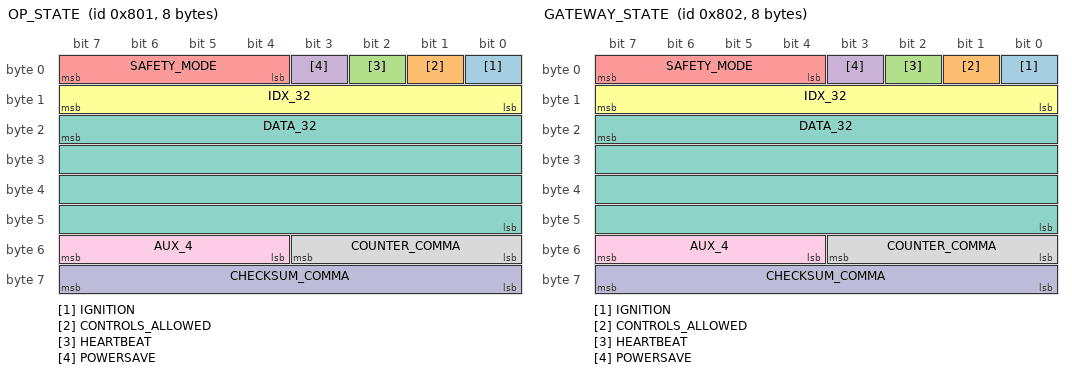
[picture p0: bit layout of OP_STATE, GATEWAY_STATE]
BO_ 2049 OP_STATE: 8 OP
 SG_ IGNITION : 0|1@0+ (1,0) [0|0] "" XXX
 SG_ CONTROLS_ALLOWED : 1|1@0+ (1,0) [0|0] "" XXX
 SG_ HEARTBEAT : 2|1@0+ (1,0) [0|0] "" XXX
 SG_ POWERSAVE : 3|1@0+ (1,0) [0|0] "" XXX
 SG_ SAFETY_MODE : 7|4@0+ (1,0) [0|0] "" XXX
 SG_ IDX_32 : 15|8@0+ (1,0) [0|0] "" XXX
 SG_ DATA_32 : 23|32@0+ (1,0) [0|0] "" XXX
 SG_ COUNTER_COMMA : 51|4@0+ (1,0) [0|0] "" XXX
 SG_ AUX_4 : 55|4@0+ (1,0) [0|0] "" XXX
 SG_ CHECKSUM_COMMA : 63|8@0+ (1,0) [0|0] "" XXX

BO_ 2050 GATEWAY_STATE: 8 GATEWAY
 SG_ IGNITION : 0|1@0+ (1,0) [0|0] "" XXX
 SG_ CONTROLS_ALLOWED : 1|1@0+ (1,0) [0|0] "" XXX
 SG_ HEARTBEAT : 2|1@0+ (1,0) [0|0] "" XXX
 SG_ POWERSAVE : 3|1@0+ (1,0) [0|0] "" XXX
 SG_ SAFETY_MODE : 7|4@0+ (1,0) [0|0] "" XXX
 SG_ IDX_32 : 15|8@0+ (1,0) [0|0] "" XXX
 SG_ DATA_32 : 23|32@0+ (1,0) [0|0] "" XXX
 SG_ COUNTER_COMMA : 51|4@0+ (1,0) [0|0] "" XXX
 SG_ AUX_4 : 55|4@0+ (1,0) [0|0] "" XXX
 SG_ CHECKSUM_COMMA : 63|8@0+ (1,0) [0|0] "" XXX

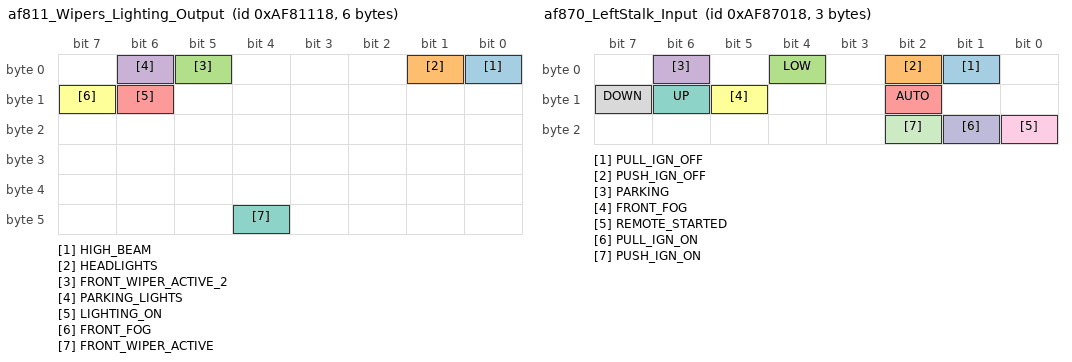
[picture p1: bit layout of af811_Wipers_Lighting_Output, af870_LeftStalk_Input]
BO_ 184029464 af811_Wipers_Lighting_Output: 6 BCM
 SG_ HIGH_BEAM : 0|1@0+ (1,0) [0|0] "" XXX
 SG_ HEADLIGHTS : 1|1@0+ (1,0) [0|0] "" XXX
 SG_ FRONT_WIPER_ACTIVE_2 : 5|1@0+ (1,0) [0|0] "" XXX
 SG_ PARKING_LIGHTS : 6|1@0+ (1,0) [0|0] "" XXX
 SG_ LIGHTING_ON : 14|1@0+ (1,0) [0|1] "" XXX
 SG_ FRONT_FOG : 15|1@0+ (1,0) [0|1] "" XXX
 SG_ FRONT_WIPER_ACTIVE : 44|1@0+ (1,0) [0|0] "" XXX

BO_ 184053784 af870_LeftStalk_Input: 3 BCM
 SG_ PULL_IGN_OFF : 1|1@0+ (1,0) [0|0] "" XXX
 SG_ PUSH_IGN_OFF : 2|1@0+ (1,0) [0|0] "" XXX
 SG_ LOW : 4|1@0+ (1,0) [0|0] "" XXX
 SG_ PARKING : 6|1@0+ (1,0) [0|0] "" XXX
 SG_ AUTO : 10|1@0+ (1,0) [0|0] "" XXX
 SG_ FRONT_FOG : 13|1@0+ (1,0) [0|0] "" XXX
 SG_ UP : 14|1@0+ (1,0) [0|0] "" XXX
 SG_ DOWN : 15|1@0+ (1,0) [0|0] "" XXX
 SG_ REMOTE_STARTED : 16|1@0+ (1,0) [0|0] "" XXX
 SG_ PULL_IGN_ON : 17|1@0+ (1,0) [0|0] "" XXX
 SG_ PUSH_IGN_ON : 18|1@0+ (1,0) [0|0] "" XXX

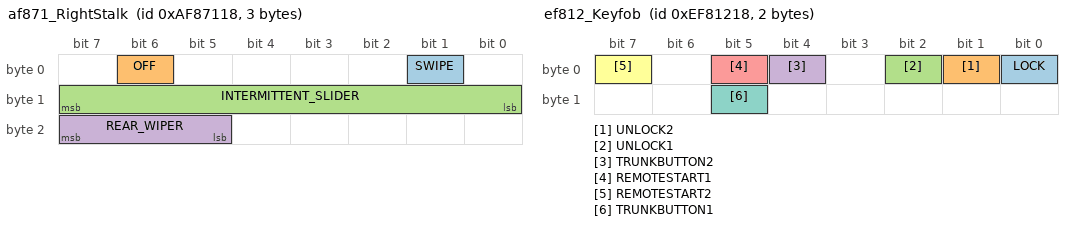
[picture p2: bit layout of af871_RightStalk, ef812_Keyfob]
BO_ 184054040 af871_RightStalk: 3 BCM
 SG_ SWIPE : 1|1@0+ (1,0) [0|0] "" XXX
 SG_ OFF : 6|1@0+ (1,0) [0|0] "" XXX
 SG_ INTERMITTENT_SLIDER : 15|8@0+ (1,0) [0|0] "" XXX
 SG_ REAR_WIPER : 23|3@0+ (1,0) [0|0] "" XXX

BO_ 184057168 af87d: 2 Meter

BO_ 184057368 af87e: 3 BCM

BO_ 184121680 af979: 1 Meter

BO_ 251138584 ef812_Keyfob: 2 BCM
 SG_ LOCK : 0|1@0+ (1,0) [0|0] "" XXX
 SG_ UNLOCK2 : 1|1@0+ (1,0) [0|0] "" XXX
 SG_ UNLOCK1 : 2|1@0+ (1,0) [0|0] "" XXX
 SG_ TRUNKBUTTON2 : 4|1@0+ (1,0) [0|0] "" XXX
 SG_ REMOTESTART1 : 5|1@0+ (1,0) [0|0] "" XXX
 SG_ REMOTESTART2 : 7|1@0+ (1,0) [0|0] "" XXX
 SG_ TRUNKBUTTON1 : 13|1@0+ (1,0) [0|0] "" XXX

BO_ 251138840 ef813: 6 RemoteSrtOrWakeup

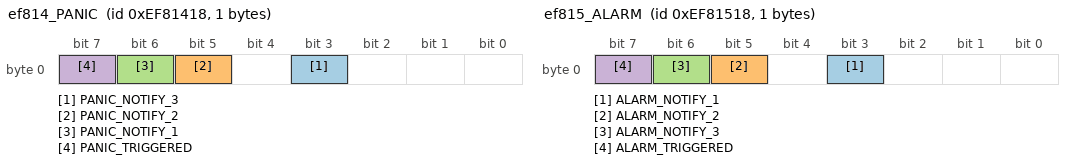
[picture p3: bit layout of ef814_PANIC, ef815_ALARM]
BO_ 251139096 ef814_PANIC: 1 BCM
 SG_ PANIC_NOTIFY_3 : 3|1@0+ (1,0) [0|0] "" XXX
 SG_ PANIC_NOTIFY_2 : 5|1@0+ (1,0) [0|0] "" XXX
 SG_ PANIC_NOTIFY_1 : 6|1@0+ (1,0) [0|0] "" XXX
 SG_ PANIC_TRIGGERED : 7|1@0+ (1,0) [0|0] "" XXX

BO_ 251139352 ef815_ALARM: 1 BCM
 SG_ ALARM_NOTIFY_1 : 3|1@0+ (1,0) [0|0] "" XXX
 SG_ ALARM_NOTIFY_2 : 5|1@0+ (1,0) [0|0] "" XXX
 SG_ ALARM_NOTIFY_3 : 6|1@0+ (1,0) [0|0] "" XXX
 SG_ ALARM_TRIGGERED : 7|1@0+ (1,0) [0|0] "" XXX

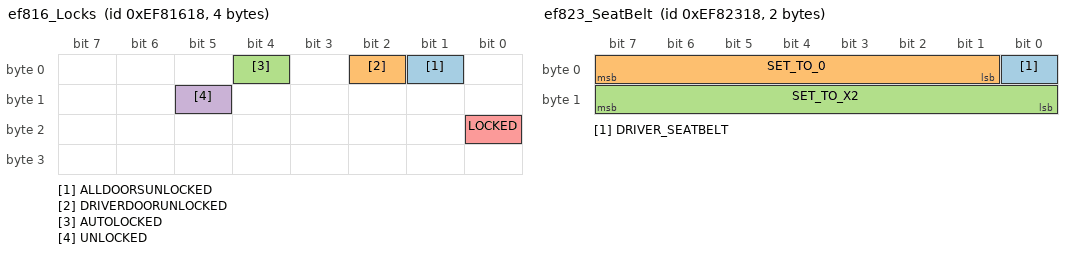
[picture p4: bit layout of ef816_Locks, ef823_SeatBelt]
BO_ 251139608 ef816_Locks: 4 BCM
 SG_ ALLDOORSUNLOCKED : 1|1@0+ (1,0) [0|0] "" XXX
 SG_ DRIVERDOORUNLOCKED : 2|1@0+ (1,0) [0|0] "" XXX
 SG_ AUTOLOCKED : 4|1@0+ (1,0) [0|0] "" XXX
 SG_ UNLOCKED : 13|1@0+ (1,0) [0|0] "" XXX
 SG_ LOCKED : 16|1@0+ (1,0) [0|0] "" XXX

BO_ 251139632 ef816: 8 RemoteSrtOrWakeup

BO_ 251142168 ef820_DoorLocks: 1 BCM
 SG_ SET_TO_0_ : 5|6@0+ (1,0) [0|0] "" XXX
 SG_ LOCKACTION_STATUS : 7|2@0+ (1,0) [0|0] "" XXX

BO_ 251142936 ef823_SeatBelt: 2 BCM
 SG_ DRIVER_SEATBELT : 0|1@0+ (1,0) [0|0] "" XXX
 SG_ SET_TO_0 : 7|7@0+ (1,0) [0|0] "" XXX
 SG_ SET_TO_X2 : 15|8@0+ (1,0) [0|0] "" XXX

BO_ 251143448 ef825: 1 RemoteSrtOrWakeup

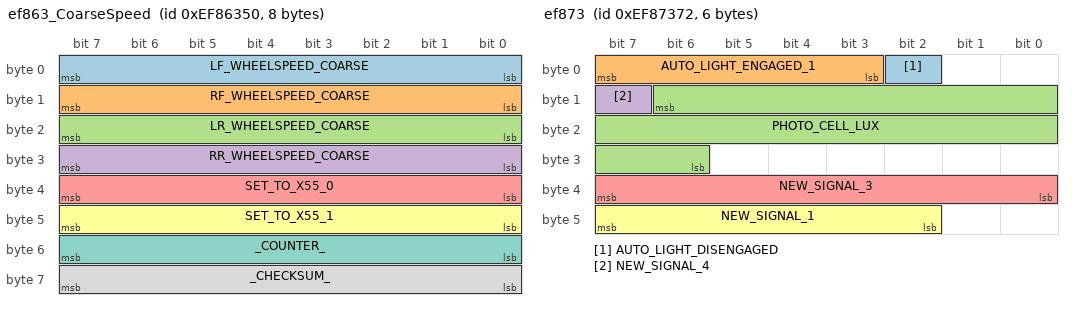
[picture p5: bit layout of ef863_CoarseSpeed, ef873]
BO_ 251159376 ef863_CoarseSpeed: 8 Meter
 SG_ LF_WHEELSPEED_COARSE : 0|8@1+ (1,0) [0|0] "" XXX
 SG_ RF_WHEELSPEED_COARSE : 8|8@1+ (1,0) [0|0] "" XXX
 SG_ LR_WHEELSPEED_COARSE : 16|8@1+ (1,0) [0|0] "" XXX
 SG_ RR_WHEELSPEED_COARSE : 24|8@1+ (1,0) [0|0] "" XXX
 SG_ SET_TO_X55_0 : 39|8@0+ (1,0) [0|0] "" XXX
 SG_ SET_TO_X55_1 : 47|8@0+ (1,0) [0|0] "" XXX
 SG_ _COUNTER_ : 55|8@0+ (1,0) [0|0] "" XXX
 SG_ _CHECKSUM_ : 63|8@0+ (1,0) [0|0] "" XXX

BO_ 251163506 ef873: 6 Solar
 SG_ AUTO_LIGHT_DISENGAGED : 2|1@0+ (1,0) [0|0] "" XXX
 SG_ AUTO_LIGHT_ENGAGED_1 : 7|5@0+ (1,0) [0|0] "" XXX
 SG_ PHOTO_CELL_LUX : 14|17@0+ (1,0) [0|0] "" XXX
 SG_ NEW_SIGNAL_4 : 15|1@0+ (1,0) [0|0] "" XXX
 SG_ NEW_SIGNAL_3 : 39|8@0+ (1,0) [0|0] "" XXX
 SG_ NEW_SIGNAL_1 : 47|6@0+ (1,0) [0|0] "" XXX

BO_ 251167000 ef881: 1 BCM

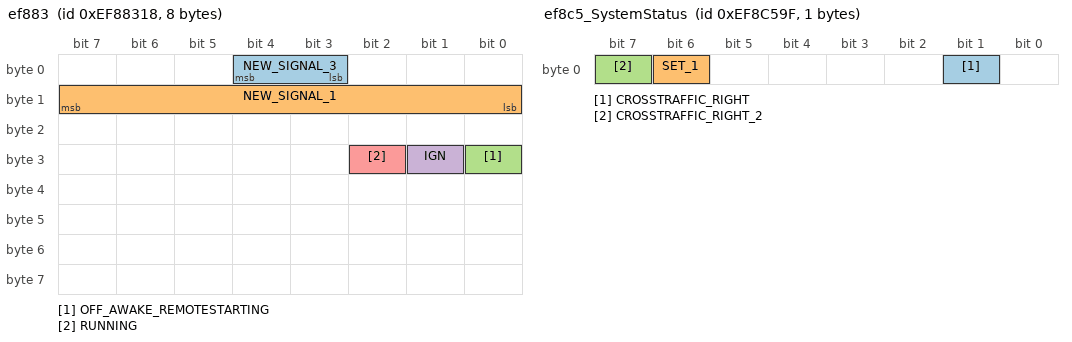
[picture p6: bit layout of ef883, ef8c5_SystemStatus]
BO_ 251167512 ef883: 8 BCM
 SG_ NEW_SIGNAL_3 : 4|2@0+ (1,0) [0|0] "" XXX
 SG_ NEW_SIGNAL_1 : 15|8@0+ (1,0) [0|0] "" XXX
 SG_ OFF_AWAKE_REMOTESTARTING : 24|1@0+ (1,0) [0|0] "" XXX
 SG_ IGN : 25|1@0+ (1,0) [0|0] "" XXX
 SG_ RUNNING : 26|1@0+ (1,0) [0|0] "" XXX

BO_ 251171864 ef894: 3 BCM

BO_ 251174936 ef8a0: 1 RemoteSrtOrWakeup

BO_ 251184543 ef8c5_SystemStatus: 1 BSI_L
 SG_ CROSSTRAFFIC_RIGHT : 1|1@0+ (1,0) [0|1] "" XXX
 SG_ SET_1 : 6|1@0+ (1,0) [0|1] "" XXX
 SG_ CROSSTRAFFIC_RIGHT_2 : 7|1@0+ (1,0) [0|1] "" XXX

BO_ 251203924 ef911: 3 Audio

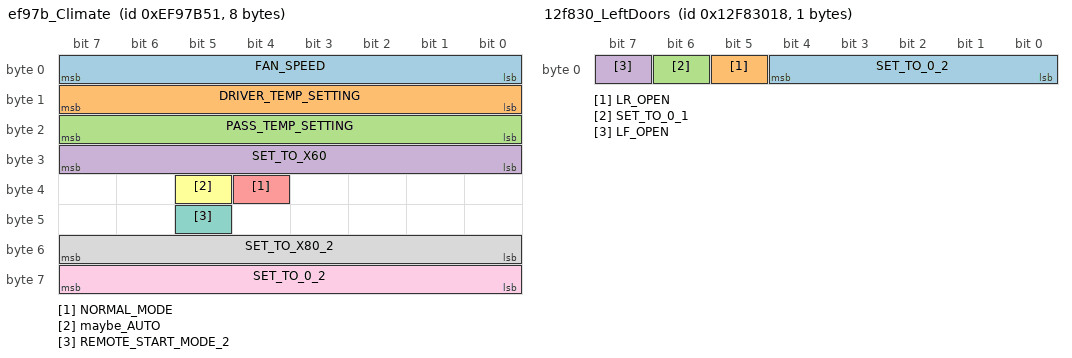
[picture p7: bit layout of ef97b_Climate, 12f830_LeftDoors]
BO_ 251231057 ef97b_Climate: 8 Climate
 SG_ FAN_SPEED : 0|8@1+ (1,0) [0|0] "" XXX
 SG_ DRIVER_TEMP_SETTING : 8|8@1+ (1,0) [0|0] "" XXX
 SG_ PASS_TEMP_SETTING : 16|8@1+ (1,0) [0|0] "" XXX
 SG_ SET_TO_X60 : 31|8@0+ (1,0) [0|0] "" XXX
 SG_ NORMAL_MODE : 36|1@0+ (1,0) [0|0] "" XXX
 SG_ maybe_AUTO : 37|1@0+ (1,0) [0|0] "" XXX
 SG_ REMOTE_START_MODE_2 : 45|1@0+ (1,0) [0|0] "" XXX
 SG_ SET_TO_X80_2 : 55|8@0+ (1,0) [0|0] "" XXX
 SG_ SET_TO_0_2 : 63|8@0+ (1,0) [0|0] "" XXX

BO_ 251234129 ef987: 3 Climate

BO_ 251234897 ef98a: 2 Climate
 SG_ TempRelated : 7|8@0+ (1,0) [0|0] "" XXX
 SG_ NEW_SIGNAL_1 : 13|6@0+ (1,0) [0|0] "" XXX
 SG_ SomeState : 15|2@0+ (1,0) [0|0] "" XXX

BO_ 251235152 ef98b_Fuel: 7 Meter
 SG_ NEW_SIGNAL_1 : 7|8@0+ (1,0) [0|0] "" XXX
 SG_ Fuel_idk : 15|8@0+ (1,0) [0|0] "" XXX
 SG_ NEW_SIGNAL_3 : 23|8@0+ (1,0) [0|0] "" XXX
 SG_ 0s : 31|32@0+ (1,0) [0|0] "" XXX

BO_ 303169360 1211ff: 0 RemoteSrtOrWakeup

BO_ 317390672 12eaff_50: 2 RemoteSrtOrWakeup

BO_ 317390673 12eaff_51: 2 RemoteSrtOrWakeup

BO_ 317390676 12eaff_QueryAllModules: 2 Audio
 SG_ NEW_SIGNAL_1 : 7|8@0+ (1,0) [0|255] "" XXX
 SG_ ReturnID : 15|8@0+ (1,0) [0|0] "" XXX

BO_ 318246936 12f810_Lighting: 6 BCM
 SG_ NEW_SIGNAL_6 : 0|3@1+ (1,0) [0|0] "" XXX
 SG_ SET_TO_1_1 : 3|1@0+ (1,0) [0|0] "" XXX
 SG_ PEDAL_BRAKE_OUTPUT : 4|1@0+ (1,0) [0|0] "" XXX
 SG_ SET_TO_1_2 : 5|1@0+ (1,0) [0|0] "" XXX
 SG_ NEW_SIGNAL_7 : 7|2@0+ (1,0) [0|0] "" XXX
 SG_ NEW_SIGNAL_5 : 15|8@0+ (1,0) [0|0] "" XXX
 SG_ NEW_SIGNAL_3 : 18|3@0+ (1,0) [0|0] "" XXX
 SG_ RIGHTSIGNAL : 19|1@0+ (1,0) [0|0] "" XXX
 SG_ LEFTSIGNAL : 20|1@0+ (1,0) [0|0] "" XXX
 SG_ HAZARDS_ENABLE : 21|1@0+ (1,0) [0|0] "" XXX
 SG_ NEW_SIGNAL_4 : 22|1@0+ (1,0) [0|0] "" XXX
 SG_ SET_TO_1_3 : 23|1@0+ (1,0) [0|0] "" XXX
 SG_ NEW_SIGNAL_2 : 30|7@0+ (1,0) [0|0] "" XXX
 SG_ REVERSE : 31|1@0+ (1,0) [0|0] "" XXX
 SG_ NEW_SIGNAL_1 : 37|6@0+ (1,0) [0|0] "" XXX
 SG_ AUTORIGHT : 38|1@0+ (1,0) [0|0] "" XXX
 SG_ AUTOLEFT : 39|1@0+ (1,0) [0|0] "" XXX
 SG_ SET_TO_C0 : 47|8@0+ (1,0) [0|0] "" XXX

BO_ 318251544 12f822: 1 BCM

BO_ 318254104 12f82c: 1 BCM

BO_ 318255128 12f830_LeftDoors: 1 BCM
 SG_ SET_TO_0_2 : 4|5@0+ (1,0) [0|0] "" XXX
 SG_ LR_OPEN : 5|1@0+ (1,0) [0|0] "" XXX
 SG_ SET_TO_0_1 : 6|1@0+ (1,0) [0|0] "" XXX
 SG_ LF_OPEN : 7|1@0+ (1,0) [0|0] "" XXX

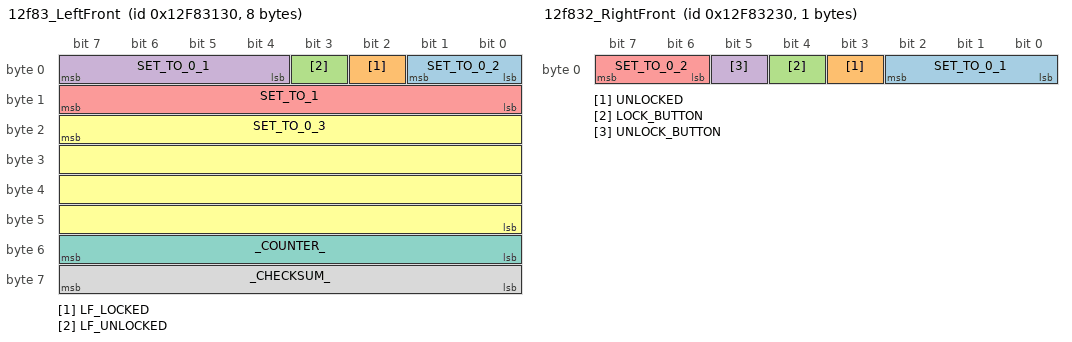
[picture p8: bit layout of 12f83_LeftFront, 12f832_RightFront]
BO_ 318255408 12f83_LeftFront: 8 WindowMain
 SG_ SET_TO_0_2 : 0|2@1+ (1,0) [0|0] "" XXX
 SG_ LF_LOCKED : 2|1@0+ (1,0) [0|0] "" XXX
 SG_ LF_UNLOCKED : 3|1@0+ (1,0) [0|0] "" XXX
 SG_ SET_TO_0_1 : 7|4@0+ (1,0) [0|0] "" XXX
 SG_ SET_TO_1 : 15|8@0+ (1,0) [0|0] "" XXX
 SG_ SET_TO_0_3 : 23|32@0+ (1,0) [0|0] "" XXX
 SG_ _COUNTER_ : 48|8@1+ (1,0) [0|0] "" XXX
 SG_ _CHECKSUM_ : 56|8@1+ (1,0) [0|0] "" XXX

BO_ 318255664 12f832_RightFront: 1 WindowMain
 SG_ SET_TO_0_1 : 0|3@1+ (1,0) [0|0] "" XXX
 SG_ UNLOCKED : 3|1@0+ (1,0) [0|0] "" XXX
 SG_ LOCK_BUTTON : 4|1@0+ (1,0) [0|0] "" XXX
 SG_ UNLOCK_BUTTON : 5|1@0+ (1,0) [0|0] "" XXX
 SG_ SET_TO_0_2 : 7|2@0+ (1,0) [0|0] "" XXX

BO_ 318256152 12f834: 1 BCM

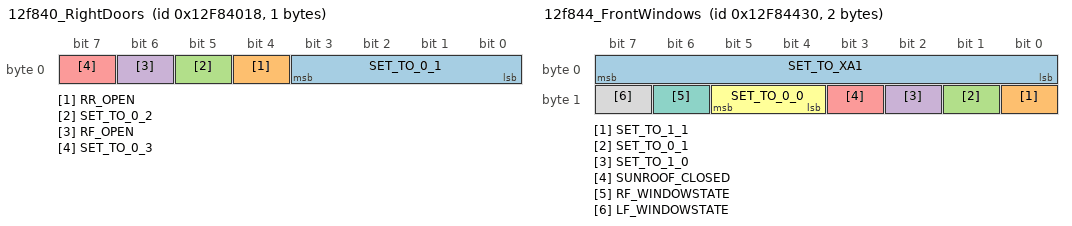
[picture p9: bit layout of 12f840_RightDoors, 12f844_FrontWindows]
BO_ 318259224 12f840_RightDoors: 1 BCM
 SG_ SET_TO_0_1 : 3|4@0+ (1,0) [0|0] "" XXX
 SG_ RR_OPEN : 4|1@0+ (1,0) [0|0] "" XXX
 SG_ SET_TO_0_2 : 5|1@0+ (1,0) [0|0] "" XXX
 SG_ RF_OPEN : 6|1@0+ (1,0) [0|0] "" XXX
 SG_ SET_TO_0_3 : 7|1@0+ (1,0) [0|0] "" XXX

BO_ 318259480 12f841_LeftRear: 1 BCM
 SG_ SET_TO_0_1 : 6|7@0+ (1,0) [0|0] "" XXX
 SG_ UNLOCKED : 7|1@0+ (1,0) [0|0] "" XXX

BO_ 318259736 12f842_RightRear: 1 BCM
 SG_ SET_TO_0_1 : 6|7@0+ (1,0) [0|0] "" XXX
 SG_ UNLOCKED : 7|1@0+ (1,0) [0|0] "" XXX

BO_ 318259992 12f843_Trunk: 1 BCM
 SG_ SET_TO_0_1 : 6|7@0+ (1,0) [0|0] "" XXX
 SG_ TRUNK_OPEN : 7|1@0+ (1,0) [0|0] "" XXX

BO_ 318260272 12f844_FrontWindows: 2 WindowMain
 SG_ SET_TO_XA1 : 7|8@0+ (1,0) [0|0] "" XXX
 SG_ SET_TO_1_1 : 8|1@0+ (1,0) [0|0] "" XXX
 SG_ SET_TO_0_1 : 9|1@0+ (1,0) [0|0] "" XXX
 SG_ SET_TO_1_0 : 10|1@0+ (1,0) [0|0] "" XXX
 SG_ SUNROOF_CLOSED : 11|1@0+ (1,0) [0|0] "" XXX
 SG_ SET_TO_0_0 : 13|2@0+ (1,0) [0|0] "" XXX
 SG_ RF_WINDOWSTATE : 14|1@0+ (1,0) [0|0] "" XXX
 SG_ LF_WINDOWSTATE : 15|1@0+ (1,0) [0|0] "" XXX

BO_ 318261784 12f84a: 1 BCM

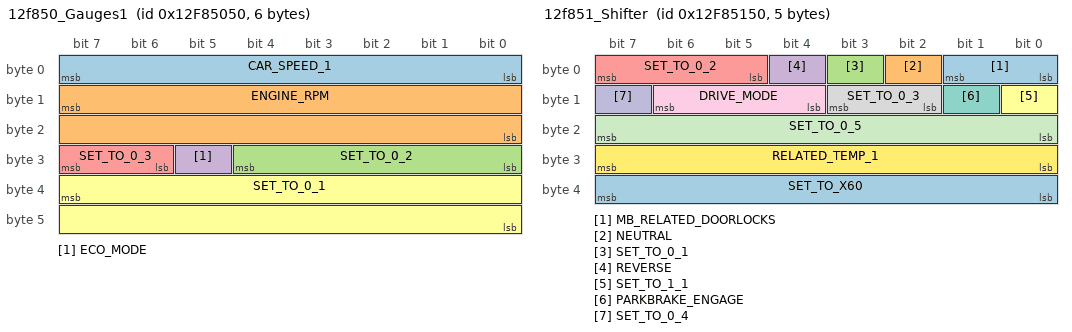
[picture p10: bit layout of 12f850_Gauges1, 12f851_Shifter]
BO_ 318263376 12f850_Gauges1: 6 Meter
 SG_ CAR_SPEED_1 : 7|8@0+ (1,0) [0|0] "" XXX
 SG_ ENGINE_RPM : 15|16@0+ (1,0) [0|0] "" XXX
 SG_ SET_TO_0_2 : 28|5@0+ (1,0) [0|0] "" XXX
 SG_ ECO_MODE : 29|1@0+ (1,0) [0|0] "" XXX
 SG_ SET_TO_0_3 : 31|2@0+ (1,0) [0|0] "" XXX
 SG_ SET_TO_0_1 : 39|16@0+ (1,0) [0|0] "" XXX

BO_ 318263632 12f851_Shifter: 5 Meter
 SG_ MB_RELATED_DOORLOCKS : 1|2@0+ (1,0) [0|0] "" XXX
 SG_ NEUTRAL : 2|1@0+ (1,0) [0|0] "" XXX
 SG_ SET_TO_0_1 : 3|1@0+ (1,0) [0|0] "" XXX
 SG_ REVERSE : 4|1@0+ (1,0) [0|0] "" XXX
 SG_ SET_TO_0_2 : 7|3@0+ (1,0) [0|0] "" XXX
 SG_ SET_TO_1_1 : 8|1@0+ (1,0) [0|0] "" XXX
 SG_ PARKBRAKE_ENGAGE : 9|1@0+ (1,0) [0|0] "" XXX
 SG_ SET_TO_0_3 : 10|2@1+ (1,0) [0|0] "" XXX
 SG_ DRIVE_MODE : 14|3@0+ (1,0) [0|0] "" XXX
 SG_ SET_TO_0_4 : 15|1@0+ (1,0) [0|0] "" XXX
 SG_ SET_TO_0_5 : 23|8@0+ (1,0) [0|0] "" XXX
 SG_ RELATED_TEMP_1 : 31|8@0+ (1,0) [0|0] "" XXX
 SG_ SET_TO_X60 : 39|8@0+ (1,0) [0|0] "" XXX

BO_ 318263888 12f852: 4 Meter

BO_ 318264145 12f853: 8 Climate
 SG_ INTERIOR_TEMP : 7|8@0+ (1,0) [0|0] "" XXX
 SG_ NEW_SIGNAL_1 : 55|16@0+ (1,0) [0|0] "" XXX

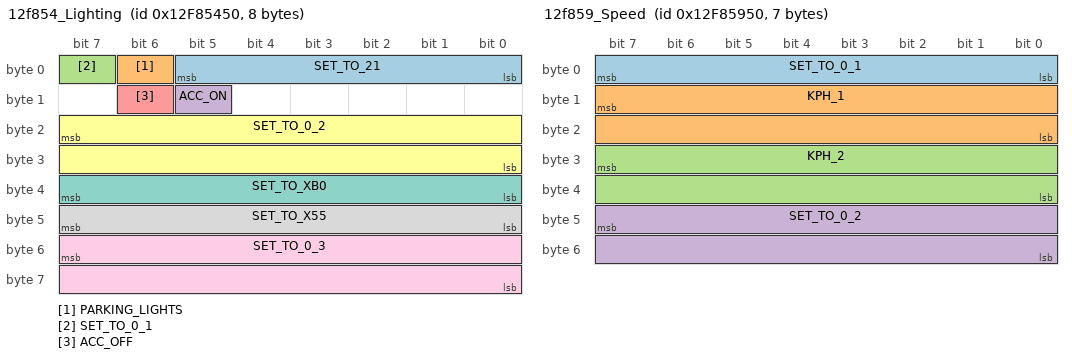
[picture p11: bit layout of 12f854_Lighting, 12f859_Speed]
BO_ 318264400 12f854_Lighting: 8 Meter
 SG_ SET_TO_21 : 5|6@0+ (1,0) [0|0] "" XXX
 SG_ PARKING_LIGHTS : 6|1@0+ (1,0) [0|0] "" XXX
 SG_ SET_TO_0_1 : 7|1@0+ (1,0) [0|0] "" XXX
 SG_ ACC_ON : 13|1@0+ (1,0) [0|0] "" XXX
 SG_ ACC_OFF : 14|1@0+ (1,0) [0|0] "" XXX
 SG_ SET_TO_0_2 : 23|16@0+ (1,0) [0|0] "" XXX
 SG_ SET_TO_XB0 : 39|8@0+ (1,0) [0|0] "" XXX
 SG_ SET_TO_X55 : 47|8@0+ (1,0) [0|0] "" XXX
 SG_ SET_TO_0_3 : 55|16@0+ (1,0) [0|0] "" XXX

BO_ 318265425 12f858: 6 Climate
 SG_ INTERIOR_TEMP : 7|8@0+ (1,0) [0|0] "" XXX
 SG_ EXTERIOR_TEMP : 31|8@0+ (1,0) [0|0] "" XXX

BO_ 318265680 12f859_Speed: 7 Meter
 SG_ SET_TO_0_1 : 7|8@0+ (1,0) [0|0] "" XXX
 SG_ KPH_1 : 15|16@0+ (0.01,0) [0|0] "" XXX
 SG_ KPH_2 : 31|16@0+ (0.01,0) [0|0] "" XXX
 SG_ SET_TO_0_2 : 47|16@0+ (1,0) [0|0] "" XXX

BO_ 318266448 12f85c: 6 Meter

BO_ 318267728 12f861: 8 Meter

BO_ 318273560 12f878: 1 BCM

BO_ 318275608 12f880_TrunkButton: 1 BCM
 SG_ SET_TO_0_1 : 6|7@0+ (1,0) [0|0] "" XXX
 SG_ RELEASE_BUTTON : 7|1@0+ (1,0) [0|0] "" XXX

BO_ 318279704 12f890: 4 BCM
 SG_ State_idk : 8|2@1+ (1,0) [0|0] "" XXX
 SG_ Starter_idk : 26|1@0+ (1,0) [0|0] "" XXX

BO_ 318284336 12f8a2: 8 WindowMain

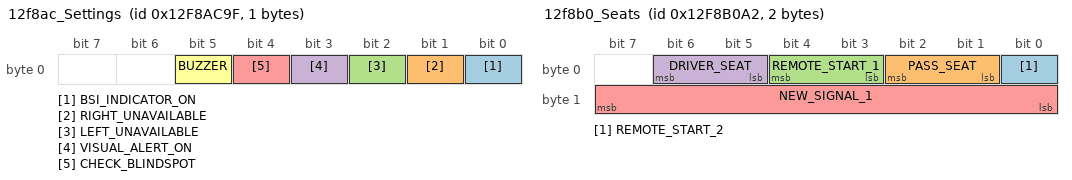
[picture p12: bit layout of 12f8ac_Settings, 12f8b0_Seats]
BO_ 318287007 12f8ac_Settings: 1 BSI_L
 SG_ BSI_INDICATOR_ON : 0|1@0+ (1,0) [0|1] "" XXX
 SG_ RIGHT_UNAVAILABLE : 1|1@0+ (1,0) [0|1] "" XXX
 SG_ LEFT_UNAVAILABLE : 2|1@0+ (1,0) [0|1] "" XXX
 SG_ VISUAL_ALERT_ON : 3|1@0+ (1,0) [0|1] "" XXX
 SG_ CHECK_BLINDSPOT : 4|1@0+ (1,0) [0|3] "" XXX
 SG_ BUZZER : 5|1@0+ (1,0) [0|1] "" XXX

BO_ 318288034 12f8b0_Seats: 2 HeatedSeats
 SG_ REMOTE_START_2 : 0|1@0+ (1,0) [0|0] "" XXX
 SG_ PASS_SEAT : 2|2@0+ (1,0) [0|0] "" XXX
 SG_ REMOTE_START_1 : 4|2@0+ (1,0) [0|0] "" XXX
 SG_ DRIVER_SEAT : 6|2@0+ (1,0) [0|0] "" XXX
 SG_ NEW_SIGNAL_1 : 15|8@0+ (1,0) [0|0] "" XXX

BO_ 318288209 12f8b1: 4 Climate

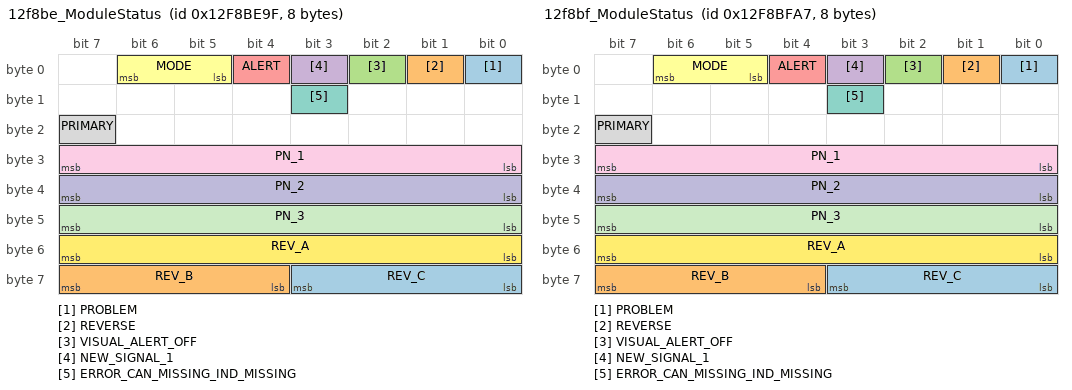
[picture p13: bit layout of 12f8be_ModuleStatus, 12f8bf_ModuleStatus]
BO_ 318291615 12f8be_ModuleStatus: 8 BSI_L
 SG_ PROBLEM : 0|1@0+ (1,0) [0|1] "" XXX
 SG_ REVERSE : 1|1@0+ (1,0) [0|1] "" XXX
 SG_ VISUAL_ALERT_OFF : 2|1@0+ (1,0) [0|1] "" XXX
 SG_ NEW_SIGNAL_1 : 3|1@0+ (1,0) [0|1] "" XXX
 SG_ ALERT : 4|1@0+ (1,0) [0|0] "" XXX
 SG_ MODE : 6|2@0+ (1,0) [0|0] "" XXX
 SG_ ERROR_CAN_MISSING_IND_MISSING : 11|1@0+ (1,0) [0|1] "" XXX
 SG_ PRIMARY : 23|1@0+ (1,0) [0|0] "" XXX
 SG_ PN_1 : 31|8@0+ (1,0) [0|0] "" XXX
 SG_ PN_2 : 39|8@0+ (1,0) [0|0] "" XXX
 SG_ PN_3 : 47|8@0+ (1,0) [0|0] "" XXX
 SG_ REV_A : 55|8@0+ (1,0) [0|0] "" XXX
 SG_ REV_C : 59|4@0+ (1,0) [0|0] "" XXX
 SG_ REV_B : 63|4@0+ (1,0) [0|0] "" XXX

BO_ 318291879 12f8bf_ModuleStatus: 8 BSI_R
 SG_ PROBLEM : 0|1@0+ (1,0) [0|1] "" XXX
 SG_ REVERSE : 1|1@0+ (1,0) [0|1] "" XXX
 SG_ VISUAL_ALERT_OFF : 2|1@0+ (1,0) [0|1] "" XXX
 SG_ NEW_SIGNAL_1 : 3|1@0+ (1,0) [0|1] "" XXX
 SG_ ALERT : 4|1@0+ (1,0) [0|0] "" XXX
 SG_ MODE : 6|2@0+ (1,0) [0|0] "" XXX
 SG_ ERROR_CAN_MISSING_IND_MISSING : 11|1@0+ (1,0) [0|1] "" XXX
 SG_ PRIMARY : 23|1@0+ (1,0) [0|0] "" XXX
 SG_ PN_1 : 31|8@0+ (1,0) [0|0] "" XXX
 SG_ PN_2 : 39|8@0+ (1,0) [0|0] "" XXX
 SG_ PN_3 : 47|8@0+ (1,0) [0|0] "" XXX
 SG_ REV_A : 55|8@0+ (1,0) [0|0] "" XXX
 SG_ REV_C : 59|4@0+ (1,0) [0|0] "" XXX
 SG_ REV_B : 63|4@0+ (1,0) [0|0] "" XXX

BO_ 318292308 12f8c1_Location: 8 Audio
 SG_ NEW_SIGNAL_1 : 9|16@0+ (1,0) [0|16383] "" XXX
 SG_ NEW_SIGNAL_2 : 40|15@0+ (1,0) [0|16383] "" XXX

BO_ 318300244 12f8e0: 8 Audio
 SG_ NEW_SIGNAL_1 : 7|8@0+ (1,0) [0|255] "" XXX
 SG_ NEW_SIGNAL_2 : 15|8@0+ (1,0) [0|255] "" XXX
 SG_ NEW_SIGNAL_3 : 59|1@0+ (1,0) [0|1] "" XXX

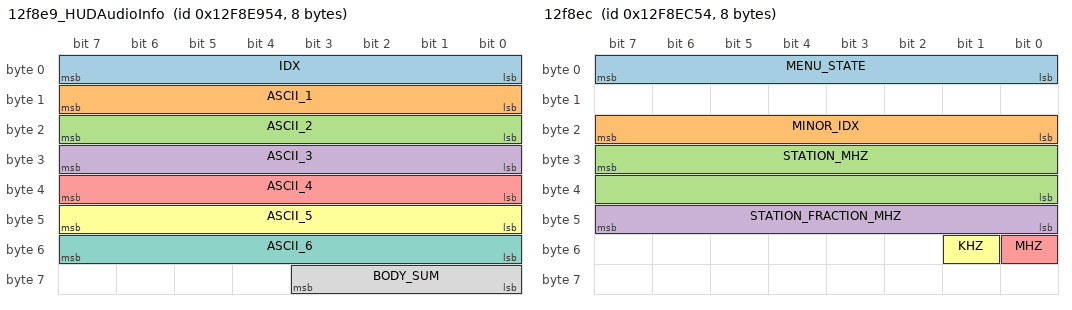
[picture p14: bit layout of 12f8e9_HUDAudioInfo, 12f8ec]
BO_ 318302548 12f8e9_HUDAudioInfo: 8 Audio
 SG_ IDX : 7|8@0+ (1,0) [0|0] "" XXX
 SG_ ASCII_1 : 15|8@0+ (1,0) [0|0] "" XXX
 SG_ ASCII_2 : 23|8@0+ (1,0) [0|0] "" XXX
 SG_ ASCII_3 : 31|8@0+ (1,0) [0|0] "" XXX
 SG_ ASCII_4 : 39|8@0+ (1,0) [0|0] "" XXX
 SG_ ASCII_5 : 47|8@0+ (1,0) [0|0] "" XXX
 SG_ ASCII_6 : 55|8@0+ (1,0) [0|0] "" XXX
 SG_ BODY_SUM : 59|4@0+ (1,0) [0|0] "" XXX

BO_ 318302800 12f8ea: 8 Meter
 SG_ CHANGES_WITH_TRACK_CHANGE : 39|8@0+ (1,0) [0|0] "" XXX

BO_ 318303316 12f8ec: 8 Audio
 SG_ MENU_STATE : 7|8@0+ (1,0) [0|0] "" XXX
 SG_ MINOR_IDX : 23|8@0+ (1,0) [0|0] "" XXX
 SG_ STATION_MHZ : 31|16@0+ (1,0) [0|0] "" XXX
 SG_ STATION_FRACTION_MHZ : 47|8@0+ (1,0) [0|0] "" XXX
 SG_ MHZ : 48|1@0+ (1,0) [0|0] "" XXX
 SG_ KHZ : 49|1@0+ (1,0) [0|0] "" XXX

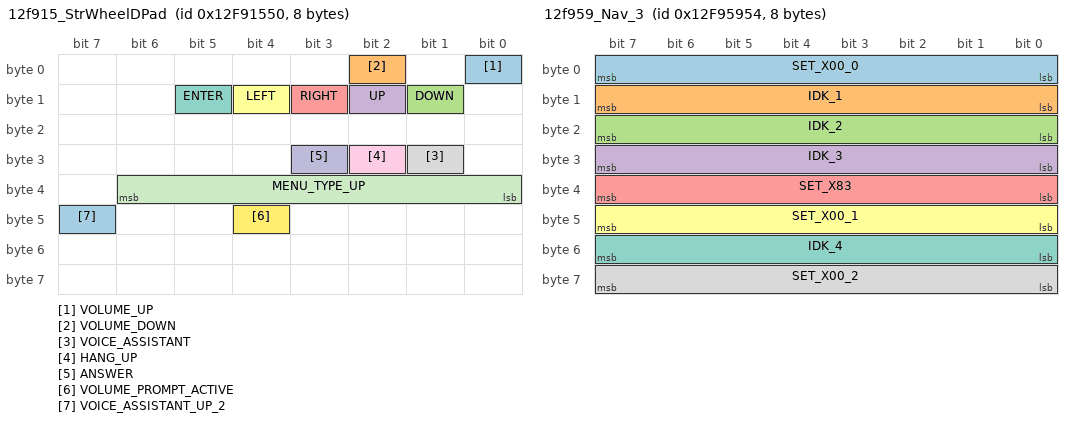
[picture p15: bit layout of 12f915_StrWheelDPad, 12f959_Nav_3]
BO_ 318313808 12f915_StrWheelDPad: 8 Meter
 SG_ VOLUME_UP : 0|1@0+ (1,0) [0|0] "" XXX
 SG_ VOLUME_DOWN : 2|1@0+ (1,0) [0|0] "" XXX
 SG_ DOWN : 9|1@0+ (1,0) [0|0] "" XXX
 SG_ UP : 10|1@0+ (1,0) [0|0] "" XXX
 SG_ RIGHT : 11|1@0+ (1,0) [0|0] "" XXX
 SG_ LEFT : 12|1@0+ (1,0) [0|0] "" XXX
 SG_ ENTER : 13|1@0+ (1,0) [0|0] "" XXX
 SG_ VOICE_ASSISTANT : 25|1@0+ (1,0) [0|0] "" XXX
 SG_ HANG_UP : 26|1@0+ (1,0) [0|0] "" XXX
 SG_ ANSWER : 27|1@0+ (1,0) [0|0] "" XXX
 SG_ MENU_TYPE_UP : 38|7@0+ (1,0) [0|0] "" XXX
 SG_ VOLUME_PROMPT_ACTIVE : 44|1@0+ (1,0) [0|0] "" XXX
 SG_ VOICE_ASSISTANT_UP_2 : 47|1@0+ (1,0) [0|0] "" XXX

BO_ 318314580 12f918: 4 Audio

BO_ 318329172 12f951: 4 Audio

BO_ 318330196 12f955: 2 Audio

BO_ 318331220 12f959_Nav_3: 8 Audio
 SG_ SET_X00_0 : 7|8@0+ (1,0) [0|0] "" XXX
 SG_ IDK_1 : 8|8@1+ (1,0) [0|0] "" XXX
 SG_ IDK_2 : 23|8@0+ (1,0) [0|0] "" XXX
 SG_ IDK_3 : 31|8@0+ (1,0) [0|0] "" XXX
 SG_ SET_X83 : 39|8@0+ (1,0) [0|0] "" XXX
 SG_ SET_X00_1 : 47|8@0+ (1,0) [0|0] "" XXX
 SG_ IDK_4 : 55|8@0+ (1,0) [0|0] "" XXX
 SG_ SET_X00_2 : 63|8@0+ (1,0) [0|0] "" XXX

BO_ 318331732 12f95b_Nav_4: 8 Audio
 SG_ SET_X20 : 7|8@0+ (1,0) [0|0] "" XXX
 SG_ SET_X15 : 23|8@0+ (1,0) [0|0] "" XXX
 SG_ SET_X03 : 31|8@0+ (1,0) [0|0] "" XXX

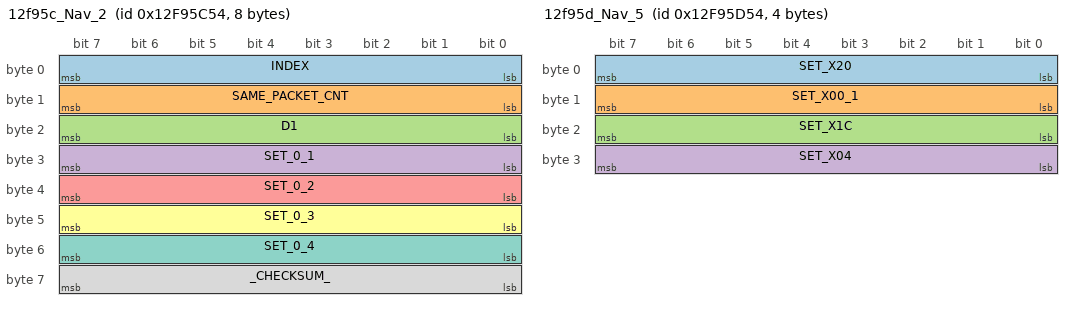
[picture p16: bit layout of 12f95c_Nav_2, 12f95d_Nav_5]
BO_ 318331988 12f95c_Nav_2: 8 Audio
 SG_ INDEX : 0|8@1+ (1,0) [0|0] "" XXX
 SG_ SAME_PACKET_CNT : 15|8@0+ (1,0) [0|0] "" XXX
 SG_ D1 : 23|8@0+ (1,0) [0|0] "" XXX
 SG_ SET_0_1 : 31|8@0+ (1,0) [0|0] "" XXX
 SG_ SET_0_2 : 39|8@0+ (1,0) [0|0] "" XXX
 SG_ SET_0_3 : 47|8@0+ (1,0) [0|0] "" XXX
 SG_ SET_0_4 : 55|8@0+ (1,0) [0|0] "" XXX
 SG_ _CHECKSUM_ : 63|8@0+ (1,0) [0|0] "" XXX

BO_ 318332244 12f95d_Nav_5: 4 Audio
 SG_ SET_X20 : 7|8@0+ (1,0) [0|0] "" XXX
 SG_ SET_X00_1 : 15|8@0+ (1,0) [0|0] "" XXX
 SG_ SET_X1C : 23|8@0+ (1,0) [0|0] "" XXX
 SG_ SET_X04 : 31|8@0+ (1,0) [0|0] "" XXX

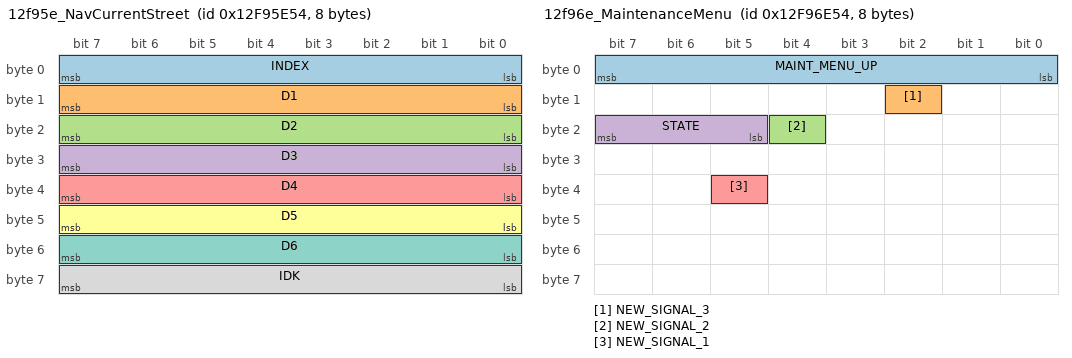
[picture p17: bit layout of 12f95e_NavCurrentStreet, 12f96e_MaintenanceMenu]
BO_ 318332500 12f95e_NavCurrentStreet: 8 Audio
 SG_ INDEX : 7|8@0+ (1,0) [0|0] "" XXX
 SG_ D1 : 8|8@1+ (1,0) [0|0] "" XXX
 SG_ D2 : 16|8@1+ (1,0) [0|0] "" XXX
 SG_ D3 : 24|8@1+ (1,0) [0|0] "" XXX
 SG_ D4 : 32|8@1+ (1,0) [0|0] "" XXX
 SG_ D5 : 40|8@1+ (1,0) [0|0] "" XXX
 SG_ D6 : 48|8@1+ (1,0) [0|0] "" XXX
 SG_ IDK : 56|8@1+ (1,0) [0|0] "" XXX

BO_ 318332752 12f95f: 8 Meter
 SG_ NEW_SIGNAL_1 : 7|24@0+ (0.0176,0) [0|0] "" XXX

BO_ 318333008 12f960: 7 Meter
 SG_ NEW_SIGNAL_1 : 7|8@0+ (1,0) [0|0] "" XXX
 SG_ NEW_SIGNAL_2 : 15|8@0+ (1,0) [0|0] "" XXX
 SG_ NEW_SIGNAL_3 : 23|8@0+ (1,0) [0|0] "" XXX
 SG_ NEW_SIGNAL_4 : 31|8@0+ (1,0) [0|0] "" XXX
 SG_ NEW_SIGNAL_5 : 39|8@0+ (1,0) [0|0] "" XXX
 SG_ NEW_SIGNAL_6 : 47|8@0+ (1,0) [0|0] "" XXX
 SG_ NEW_SIGNAL_7 : 55|8@0+ (1,0) [0|0] "" XXX

BO_ 318333264 12f961: 7 Meter

BO_ 318333520 12f962: 7 Meter
 SG_ NEW_SIGNAL_2 : 7|8@0+ (1,0) [0|255] "" XXX
 SG_ NEW_SIGNAL_1 : 15|8@0+ (1,0) [0|255] "" XXX

BO_ 318334800 12f967: 8 Meter

BO_ 318335824 12f96b: 8 Meter

BO_ 318336336 12f96d: 8 Meter

BO_ 318336596 12f96e_MaintenanceMenu: 8 Audio
 SG_ MAINT_MENU_UP : 7|8@0+ (1,0) [0|0] "" XXX
 SG_ NEW_SIGNAL_3 : 10|1@0+ (1,0) [0|1] "" XXX
 SG_ NEW_SIGNAL_2 : 20|1@0+ (1,0) [0|1] "" XXX
 SG_ STATE : 23|3@0+ (1,0) [0|0] "" XXX
 SG_ NEW_SIGNAL_1 : 37|1@0+ (1,0) [0|1] "" XXX

BO_ 318337360 12f971_Steer: 3 Meter
 SG_ SET_TO_XE0 : 7|8@0+ (1,0) [0|0] "" XXX
 SG_ STEER_ANGLE : 15|16@0- (1,0) [0|0] "" XXX

BO_ 318337872 12f973: 2 Meter

BO_ 318338128 12f974: 2 Meter

BO_ 318338640 12f976: 1 Meter

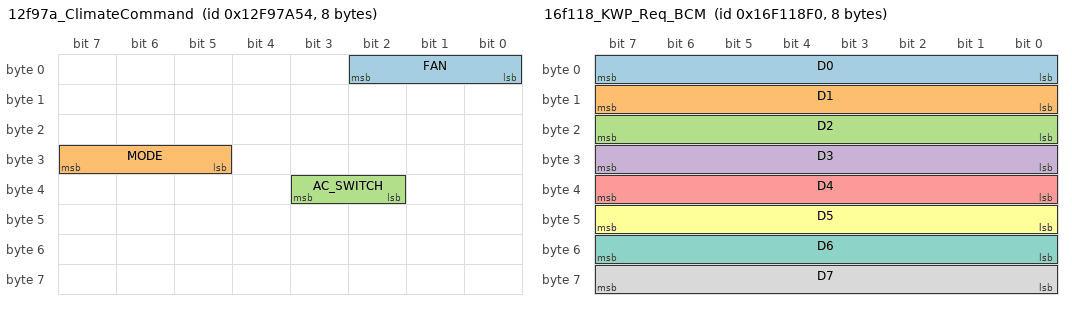
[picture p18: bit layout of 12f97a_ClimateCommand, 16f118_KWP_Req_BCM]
BO_ 318339668 12f97a_ClimateCommand: 8 Audio
 SG_ FAN : 0|3@1+ (1,0) [0|0] "" XXX
 SG_ MODE : 31|3@0+ (1,0) [0|0] "" XXX
 SG_ AC_SWITCH : 34|2@1+ (1,0) [0|0] "" XXX

BO_ 318340176 12f97c: 1 Meter
 SG_ IGN2_STARTED : 3|1@0+ (1,0) [0|0] "" XXX
 SG_ IGN : 4|1@0+ (1,0) [0|0] "" XXX

BO_ 318343249 12f988: 3 BCM
 SG_ NEW_SIGNAL_1 : 5|2@0+ (1,0) [0|3] "" XXX

BO_ 318357584 12f9c0: 8 Meter

BO_ 318357840 12f9c1: 8 Meter

BO_ 318358096 12f9c2: 4 Meter

BO_ 318358352 12f9c3: 8 Meter

BO_ 318358612 12f9c: 4 Audio

BO_ 318358868 12f9c5: 8 Audio
 SG_ NEW_SIGNAL_1 : 7|8@0+ (1,0) [0|255] "" XXX
 SG_ NEW_SIGNAL_2 : 15|8@0+ (1,0) [0|255] "" XXX
 SG_ NEW_SIGNAL_3 : 23|8@0+ (1,0) [0|255] "" XXX
 SG_ NEW_SIGNAL_4 : 31|8@0+ (1,0) [0|255] "" XXX
 SG_ NEW_SIGNAL_5 : 39|8@0+ (1,0) [0|255] "" XXX
 SG_ NEW_SIGNAL_6 : 47|8@0+ (1,0) [0|255] "" XXX
 SG_ NEW_SIGNAL_7 : 55|8@0+ (1,0) [0|255] "" XXX
 SG_ NEW_SIGNAL_8 : 63|8@0+ (1,0) [0|255] "" XXX

BO_ 318361624 12f9d0: 1 BCM

BO_ 370212632 1610ff_Ping: 0 BCM

BO_ 370212656 1610ff_Ping: 0 WindowMain

BO_ 370212688 1610ff_Ping: 0 Meter

BO_ 370212689 1610ff_Ping: 0 Climate

BO_ 370212692 1610ff_Ping: 0 Audio

BO_ 370212722 1610ff_Ping: 0 Solar

BO_ 370212767 1610ff_Ping: 1 BSI_L

BO_ 370212770 1610ff_Ping: 0 HeatedSeats

BO_ 370212775 1610ff_Pingg: 1 BSI_R

BO_ 372250708 1630_18: 8 Audio

BO_ 372265044 Query_Meter_163050: 8 Audio

BO_ 372266008 Reply_Audio_1630: 3 BCM

BO_ 372266064 Reply_Audio_163054: 3 Meter

BO_ 372266098 Reply_Audio_1630: 3 Solar

BO_ 372266143 Audio_BSI_Settings_1630: 3 BSI_L
 SG_ ALERT_MODE_SET_VIA_AUDIO M : 17|2@0+ (1,0) [0|255] "" XXX
 SG_ NEW_SIGNAL_1 : 6|1@0+ (1,0) [0|1] "" XXX

BO_ 372273748 1630_Solar: 8 Audio

BO_ 372285268 resp_BSI_L_1630: 3 Audio
 SG_ NEW_SIGNAL_1 : 6|1@0+ (1,0) [0|1] "" XXX
 SG_ NEW_SIGNAL_2 : 16|1@0+ (1,0) [0|1] "" XXX

BO_ 372331544 Reply_Audio_1631: 8 BCM

BO_ 372331568 Reply_Audio_1631: 8 WindowMain

BO_ 372331600 Reply_Audio_1631: 8 Meter

BO_ 372331634 _Reply_Audio_1631: 8 Solar

BO_ 372331679 TO_AUDIO_1631: 8 BSI_L

BO_ 384899156 16f118_PingBCM: 2 Audio

BO_ 384899231 L_16f118_KWP_Resp: 2 XXX

BO_ 384899239 R_16f118_KWP_Resp: 2 XXX

BO_ 384899312 16f118_KWP_Req_BCM: 8 Tester
 SG_ D0 : 7|8@0+ (1,0) [0|0] "" XXX
 SG_ D1 : 15|8@0+ (1,0) [0|0] "" XXX
 SG_ D2 : 23|8@0+ (1,0) [0|0] "" XXX
 SG_ D3 : 31|8@0+ (1,0) [0|0] "" XXX
 SG_ D4 : 39|8@0+ (1,0) [0|0] "" XXX
 SG_ D5 : 47|8@0+ (1,0) [0|0] "" XXX
 SG_ D6 : 55|8@0+ (1,0) [0|0] "" XXX
 SG_ D7 : 63|8@0+ (1,0) [0|0] "" XXX

BO_ 384913492 Query_Meter_16f150: 2 Audio

BO_ 384913748 16f151: 2 Audio

BO_ 384914456 16f154_PingAudio: 8 BCM

BO_ 384914512 Reply_Audio_16f154: 8 Meter

BO_ 384914513 16f154: 8 Climate

BO_ 384914594 16f154: 8 HeatedSeats

BO_ 384933656 L_16f118_KWP_Req: 8 XXX

BO_ 384934484 16f1a2: 2 Audio

BO_ 384935704 R_16f118_KWP_Req: 8 XXX

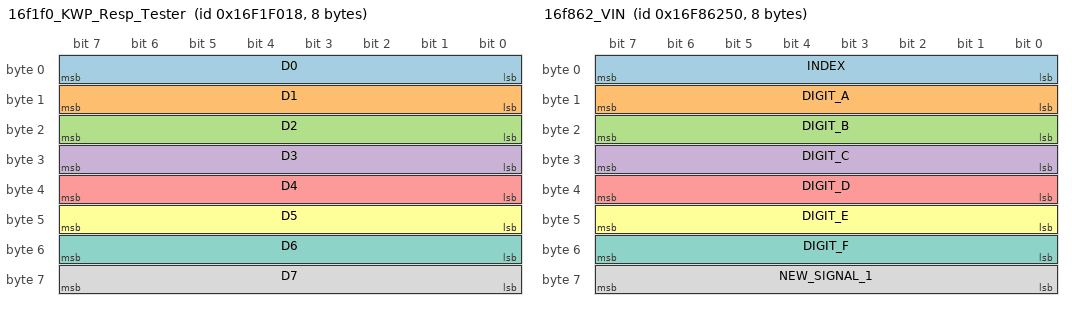
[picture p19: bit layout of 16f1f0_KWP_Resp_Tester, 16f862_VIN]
BO_ 384954392 16f1f0_KWP_Resp_Tester: 8 BCM
 SG_ D0 : 7|8@0+ (1,0) [0|0] "" XXX
 SG_ D1 : 15|8@0+ (1,0) [0|0] "" XXX
 SG_ D2 : 23|8@0+ (1,0) [0|0] "" XXX
 SG_ D3 : 31|8@0+ (1,0) [0|0] "" XXX
 SG_ D4 : 39|8@0+ (1,0) [0|0] "" XXX
 SG_ D5 : 47|8@0+ (1,0) [0|0] "" XXX
 SG_ D6 : 55|8@0+ (1,0) [0|0] "" XXX
 SG_ D7 : 63|8@0+ (1,0) [0|0] "" XXX

BO_ 384979992 16f254_ResponseToAudioUnit_0x12eaff54: 2 BCM

BO_ 384980016 16f254_ResponseToAudioUnit_0x12eaff54: 2 WindowMain

BO_ 384980048 16f254_ResponseToAudioUnit_0x12eaff54: 2 Meter

BO_ 384980049 16f254_ResponseToAudioUnit_0x12eaff54: 2 Climate

BO_ 384980082 16f254_ResponseToAudioUnit_0x12eaff54: 2 Solar

BO_ 384980127 16f254_L_TO_AUDIO: 2 BSI_L

BO_ 384980130 16f254_ResponseToAudioUnit_0x12eaff54: 2 HeatedSeats

BO_ 384980135 16f254_R_TO_AUDIO: 2 BSI_R

BO_ 385376848 16f862_VIN: 8 Meter
 SG_ INDEX : 7|8@0+ (1,0) [0|0] "" XXX
 SG_ DIGIT_A : 15|8@0+ (1,0) [0|0] "" XXX
 SG_ DIGIT_B : 23|8@0+ (1,0) [0|0] "" XXX
 SG_ DIGIT_C : 31|8@0+ (1,0) [0|0] "" XXX
 SG_ DIGIT_D : 39|8@0+ (1,0) [0|0] "" XXX
 SG_ DIGIT_E : 47|8@0+ (1,0) [0|0] "" XXX
 SG_ DIGIT_F : 55|8@0+ (1,0) [0|0] "" XXX
 SG_ NEW_SIGNAL_1 : 63|8@0+ (1,0) [0|0] "" XXX

BO_ 385449300 16f97d: 8 Audio
 SG_ NEW_SIGNAL_1 : 6|1@0+ (1,0) [0|1] "" XXX
 SG_ COUNTER : 47|16@0+ (1,0) [0|65535] "" XXX
 SG_ VALIDITY : 63|1@0+ (1,0) [0|1] "" XXX

BO_ 385450324 16f981: 1 Audio

BO_ 504561432 1e12ff_Wakeup: 0 BCM

BO_ 504561456 1e12ff_AlarmTriggered: 1 WindowMain

BO_ 504561522 1e12ff_WakeupRemoteStart: 0 Solar

BO_ 505610008 1e22ff_18: 2 RemoteSrtOrWakeup

BO_ 505610064 1e22ff_50: 2 RemoteSrtOrWakeup

CM_ BO_ 251184543 "Initially the only id active when bus is empty.";
CM_ SG_ 318287007 BSI_INDICATOR_ON "ON WITH BSI IND TEST ON";
CM_ SG_ 318287007 VISUAL_ALERT_ON "OFF WITH BSI IND TEST ON";
CM_ SG_ 318303316 MENU_STATE "16=VOLUME_CHANGE_START,20=VOLUME_CHANGE_END,96=TRACK_CHANGE_BASE,100=TRACK_CHANGE_BASE_TRACKNUMBER,108=TRACK_CHANGE_BASE_TRACKNUMBER_SONGTITLE";
CM_ SG_ 318303316 MINOR_IDX "ALSO_VOLUME_LEVEL";
CM_ BO_ 370212767 "Is always sent. Not of a request.";
VAL_ 318291615 MODE 0 "OFF" 1 "CROSSTRAFFIC REVERSE" 2 "BLINDSPOT FAST";
VAL_ 318291879 MODE 0 "OFF" 1 "CROSSTRAFFIC REVERSE" 2 "BLINDSPOT FAST";
VAL_ 372266143 ALERT_MODE_SET_VIA_AUDIO 0 "VISUAL_AUDIO_ALERT" 1 "VISUAL_ALERT" 2 "OFF";
